# STM32C552 register map
File version: 1.0.0
CPU: CM33 r0p4, little endian, MPU, FPU, 4 interrupt priority bits
Registers are 32-bit, read-write, reset 0x0 unless marked. A register's access mark holds for its fields unless they carry their own. Offsets are from the block's base; [hi:lo] are bit positions; {n}, {i} and the like mark numbered series.

## DBGMCU — DBGMCU address block description
Base 0x44024000
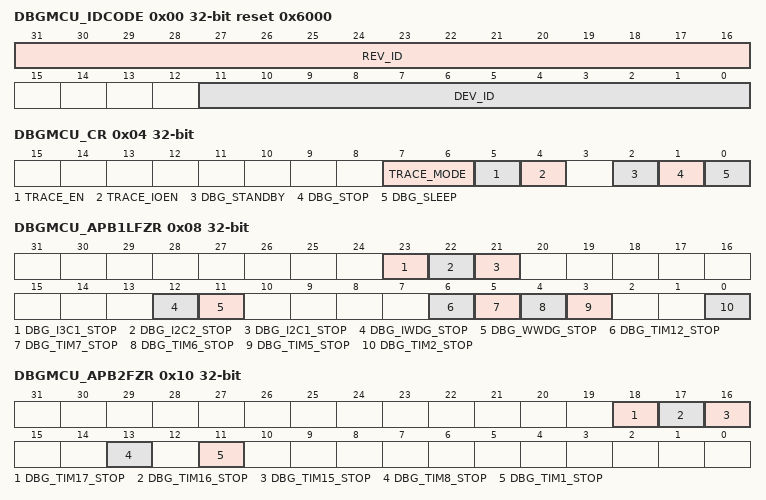
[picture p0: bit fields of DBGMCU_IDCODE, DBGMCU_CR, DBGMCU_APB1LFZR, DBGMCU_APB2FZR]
0x00 DBGMCU_IDCODE ro reset 0x6000 (reset mask 0xF000) — DBGMCU identity code register
  [31:16] REV_ID — revision
    0x1000=Revision A
  [11:0] DEV_ID — device identification
0x04 DBGMCU_CR — DBGMCU configuration register
  [7:6] TRACE_MODE — trace pin assignment
    0=trace pins assigned for asynchronous mode (TRACESWO); 1=trace pins assigned for synchronous mode with a port width of 1 (TRACECK, TRACED0); 2=trace pins assigned for synchronous mode with a port width of 2 ((TRACECK, TRACED0-1); 3=trace pins assigned for synchronous mode with a port width of 4 ((TRACECK, TRACED0-3)
  [5] TRACE_EN — trace port and clock enable.
    0=disabled; 1=enabled
  [4] TRACE_IOEN — trace pin enable
    0=disabled - trace pins not assigned; 1=enabled - trace pins assigned according to the value of TRACE_MODE field
  [2] DBG_STANDBY — Allows debug in standby mode
    0=normal operation; 1=automatic clock stop/power down disabled
  [1] DBG_STOP — Allows debug in stop mode
    0=normal operation; 1=automatic clock stop disabled
  [0] DBG_SLEEP — Allows debug in sleep mode
    0=normal operation; 1=automatic clock stop disabled
0x08 DBGMCU_APB1LFZR — DBGMCU APB1L peripheral freeze register
  [all] fields
    0=normal operation; 1=stop in debug
  [23] DBG_I3C1_STOP — I3C1 SCL stall counter stop in debug
  [22] DBG_I2C2_STOP — I2C2 SMBUS timeout stop in debug
  [21] DBG_I2C1_STOP — I2C1 SMBUS timeout stop in debug
  [12] DBG_IWDG_STOP — IWDG stop in debug
  [11] DBG_WWDG_STOP — WWDG stop in debug
  [6] DBG_TIM12_STOP — TIM12 stop in debug
  [5] DBG_TIM7_STOP — TIM7 stop in debug
  [4] DBG_TIM6_STOP — TIM6 stop in debug
  [3] DBG_TIM5_STOP — TIM5 stop in debug
  [0] DBG_TIM2_STOP — TIM2 stop in debug
0x10 DBGMCU_APB2FZR — DBGMCU APB2 peripheral freeze register
  [all] fields
    0=normal operation; 1=stop in debug
  [18] DBG_TIM17_STOP — TIM17 stop in debug
  [17] DBG_TIM16_STOP — TIM16 stop in debug
  [16] DBG_TIM15_STOP — TIM15 stop in debug
  [13] DBG_TIM8_STOP — TIM8 stop in debug
  [11] DBG_TIM1_STOP — TIM1 stop in debug
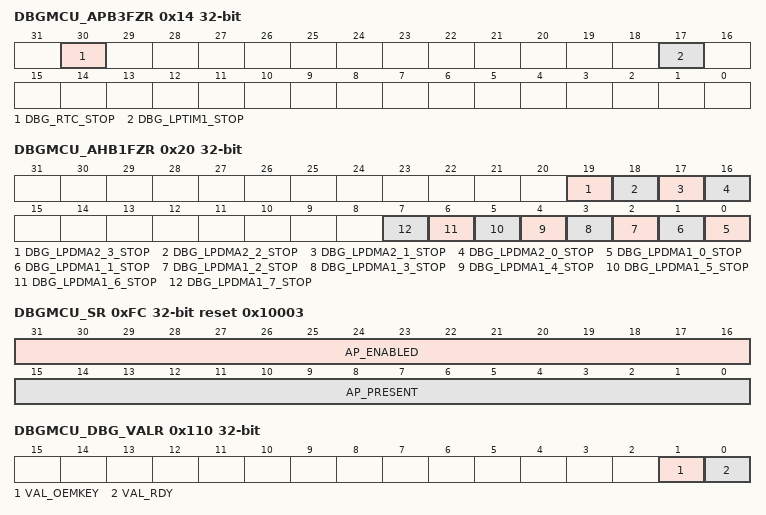
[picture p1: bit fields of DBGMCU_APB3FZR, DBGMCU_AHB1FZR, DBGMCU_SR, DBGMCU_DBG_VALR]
0x14 DBGMCU_APB3FZR — DBGMCU APB3 peripheral freeze register
  [30] DBG_RTC_STOP — RTC stop in debug
    0=normal operation; 1=stop in debug
  [17] DBG_LPTIM1_STOP — LPTIM1 stop in debug
    0=normal operation; 1=stop in debug
0x20 DBGMCU_AHB1FZR — DBGMCU AHB1 peripheral freeze register
  [all] fields
    0=normal operation; 1=stop in debug
  [19] DBG_LPDMA2_3_STOP — LPDMALPDMA2 channel 3 stop in debug
  [18] DBG_LPDMA2_2_STOP — LPDMA2 channel 2 stop in debug
  [17] DBG_LPDMA2_1_STOP — LPDMA2 channel 1 stop in debug
  [16] DBG_LPDMA2_0_STOP — LPDMA2 channel 0 stop in debug
  [n] DBG_LPDMA1_{n}_STOP (n=0..7) — LPDMA1 channel {n} stop in debug
0xFC DBGMCU_SR wo reset 0x10003 (reset mask 0xFFFF00FF) — DBGMCU status register
  [31:16] AP_ENABLED — Bit n identifies whether access port AP n is open (can be accessed via the debug port) or locked (debug access to the AP is blocked)
  [15:0] AP_PRESENT — Bit n identifies whether access port AP n is present in device
0x100 DBGMCU_DBG_AUTH_HOST wo reset not defined — DBGMCU debug authentication mailbox host register
  [31:0] AUTH_KEY — Device authentication key.
0x104 DBGMCU_DBG_AUTH_DEVICE ro reset not defined — DBGMCU debug authentication mailbox device register
  [31:0] AUTH_ID — Device specific ID.
0x10C DBGMCU_DBG_BSKEY_PWD wo — DBGMCU Boundary Scan KEY password register
  [31:0] DBG_BSKEY_PWD — Boundary scan key
0x110 DBGMCU_DBG_VALR ro — DBGMCU debug OEMKEY validation register
  [1] VAL_OEMKEY — Validation of the OEMKEY.
  [0] VAL_RDY — Validation ready.
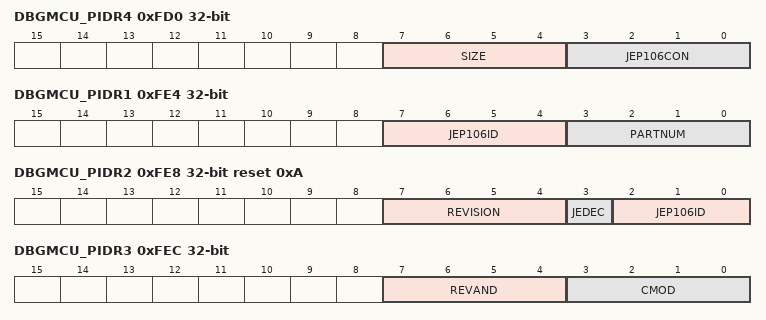
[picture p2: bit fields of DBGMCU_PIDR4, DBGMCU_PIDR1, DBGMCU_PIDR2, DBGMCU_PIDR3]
0xFD0 DBGMCU_PIDR4 ro — DBGMCU CoreSight peripheral identity register 4
  [7:4] SIZE — register file size
    0=The register file occupies a single 4-Kbyte region
  [3:0] JEP106CON — JEP106 continuation code
    0=STMicroelectronics JEDEC code
0xFE0 DBGMCU_PIDR0 ro — DBGMCU CoreSight peripheral identity register 0
  [7:0] PARTNUM — part number bits [7:0]
    0=DBGMCU part number
0xFE4 DBGMCU_PIDR1 ro — DBGMCU CoreSight peripheral identity register 1
  [7:4] JEP106ID — JEP106 identity code bits [3:0]
    0=STMicroelectronics JEDEC code
  [3:0] PARTNUM — part number bits [11:8]
    0=DBGMCU part number
0xFE8 DBGMCU_PIDR2 ro reset 0xA — DBGMCU CoreSight peripheral identity register 2
  [7:4] REVISION — component revision number
    0=r0p0
  [3] JEDEC — JEDEC assigned value
    1=designer identification specified by JEDEC
  [2:0] JEP106ID — JEP106 identity code bits [6:4]
    2=STMicroelectronics JEDEC code
0xFEC DBGMCU_PIDR3 ro — DBGMCU CoreSight peripheral identity register 3
  [7:4] REVAND — metal fix version
    0=no metal fix
  [3:0] CMOD — customer modified
    0=no customer modifications
0xFF0 DBGMCU_CIDR0 ro reset 0xD — DBGMCU CoreSight component identity register 0
  [7:0] PREAMBLE — component identification bits [7:0]
    13=common identification value
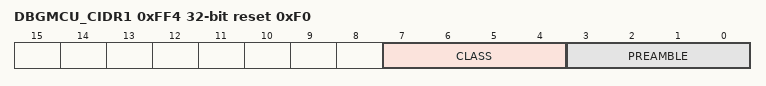
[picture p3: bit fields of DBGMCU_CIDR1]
0xFF4 DBGMCU_CIDR1 ro reset 0xF0 — DBGMCU CoreSight component identity register 1
  [7:4] CLASS — component identification bits [15:12] - component class
    15=Non-CoreSight component
  [3:0] PREAMBLE — component identification bits [11:8]
    0=common identification value
0xFF8 DBGMCU_CIDR2 ro reset 0x5 — DBGMCU CoreSight component identity register 2
  [7:0] PREAMBLE — component identification bits [23:16]
    5=common identification value
0xFFC DBGMCU_CIDR3 ro reset 0xB1 — DBGMCU CoreSight component identity register 3
  [7:0] PREAMBLE — component identification bits [31:24]
    177=common identification value

## Notices in the file
Copyright (c) 2026 STMicroelectronics.
SPDX-License-Identifier: Apache-2.0
Licensed under the Apache License, Version 2.0 (the "License");
you may not use this file except in compliance with the License.
You may obtain a copy of the License at
http://www.apache.org/licenses/LICENSE-2.0
Unless required by applicable law or agreed to in writing, software
distributed under the License is distributed on an "AS IS" BASIS,
WITHOUT WARRANTIES OR CONDITIONS OF ANY KIND, either express or implied.
See the License for the specific language governing permissions and
limitations under the License.
